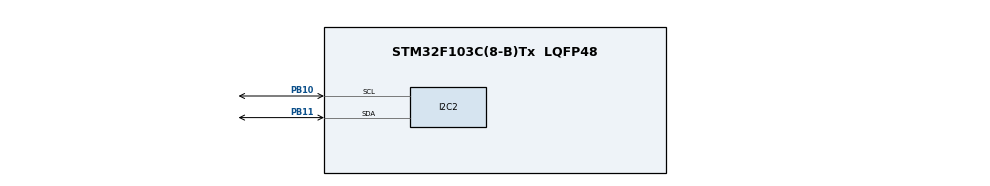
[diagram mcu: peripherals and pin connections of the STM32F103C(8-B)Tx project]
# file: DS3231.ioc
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Mcu.Family=STM32F1
Mcu.Name=STM32F103C(8-B)Tx
Mcu.Package=LQFP48
NVIC.PriorityGroup=NVIC_PRIORITYGROUP_4
PA13.Mode=Serial_Wire
PA13.Signal=SYS_JTMS-SWDIO
PA14.Mode=Serial_Wire
PA14.Signal=SYS_JTCK-SWCLK
PB10.Mode=I2C
PB10.Signal=I2C2_SCL
PB11.Mode=I2C
PB11.Signal=I2C2_SDA
ProjectManager.HeapSize=0x200
ProjectManager.StackSize=0x400
ProjectManager.TargetToolchain=MDK-ARM V5.32
RCC.APB1Freq_Value=8000000
RCC.APB2Freq_Value=8000000
board=custom

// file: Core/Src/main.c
/* USER CODE BEGIN Header */
/**
  ******************************************************************************
  * @file           : main.c
  * @brief          : Main program body
  ******************************************************************************
  * @attention
  *
  * Copyright (c) 2025 STMicroelectronics.
  * All rights reserved.
  *
  * This software is licensed under terms that can be found in the LICENSE file
  * in the root directory of this software component.
  * If no LICENSE file comes with this software, it is provided AS-IS.
  *
  ******************************************************************************
  */
/* USER CODE END Header */
#include "main.h"
#include "DS3231.h"

I2C_HandleTypeDef hi2c2;

void SystemClock_Config(void);
static void MX_GPIO_Init(void);
static void MX_I2C2_Init(void);

/* USER CODE BEGIN 0 */

#define LCD_ADDR (0x27  << 1)
#define LCD_BACKLIGHT 0x08
#define ENABLE 0x04

static void LCD_SendInternal(I2C_HandleTypeDef *hi2c, uint8_t data, uint8_t flags) {
    HAL_StatusTypeDef res;
    uint8_t up = data & 0xF0;
    uint8_t lo = (data << 4) & 0xF0;
    uint8_t data_arr[4];

    data_arr[0] = up | flags | LCD_BACKLIGHT | ENABLE;
    data_arr[1] = up | flags | LCD_BACKLIGHT;
    data_arr[2] = lo | flags | LCD_BACKLIGHT | ENABLE;
    data_arr[3] = lo | flags | LCD_BACKLIGHT;

    res = HAL_I2C_Master_Transmit(hi2c, LCD_ADDR, data_arr, 4, HAL_MAX_DELAY);
    HAL_Delay(1);
}

void LCD_SendCmd(I2C_HandleTypeDef *hi2c, char cmd) {
    LCD_SendInternal(hi2c, cmd, 0);
}

void LCD_SendData(I2C_HandleTypeDef *hi2c, char data) {
    LCD_SendInternal(hi2c, data, 1);
}

void LCD_Init(I2C_HandleTypeDef *hi2c) {
    HAL_Delay(50); // ch? LCD ?n d?nh

    LCD_SendCmd(hi2c, 0x30);
    HAL_Delay(5);
    LCD_SendCmd(hi2c, 0x30);
    HAL_Delay(1);
    LCD_SendCmd(hi2c, 0x30);
    HAL_Delay(10);

    LCD_SendCmd(hi2c, 0x20); // 4-bit mode

    // c?u hЛnh LCD
    LCD_SendCmd(hi2c, 0x28); // 4-bit, 2 line, 5x8 font
    LCD_SendCmd(hi2c, 0x08); // display off
    LCD_SendCmd(hi2c, 0x01); // clear display
    HAL_Delay(2);
    LCD_SendCmd(hi2c, 0x06); // entry mode
    LCD_SendCmd(hi2c, 0x0C); // display on, cursor off, blink off
}

void LCD_SendString(I2C_HandleTypeDef *hi2c, char *str) {
    while (*str) {
        LCD_SendData(hi2c, *str++);
    }
}

void LCD_SetCursor(I2C_HandleTypeDef *hi2c, uint8_t row, uint8_t col) {
    uint8_t addr = (row == 0) ? 0x80 : 0xC0;
    addr += col;
    LCD_SendCmd(hi2c, addr);
}

/* USER CODE END 0 */

int main(void)
{

  /* MCU Configuration--------------------------------------------------------*/

  /* Reset of all peripherals, Initializes the Flash interface and the Systick. */
  HAL_Init();

  /* Configure the system clock */
  SystemClock_Config();

  /* Initialize all configured peripherals */
  MX_GPIO_Init();
  MX_I2C2_Init();
  /* USER CODE BEGIN 2 */

	LCD_Init(&hi2c2);
  LCD_SetCursor(&hi2c2, 0, 0);
  LCD_SendString(&hi2c2, "Hello");

  /* Infinite loop */
  while (1)
  {

  }
}

void SystemClock_Config(void)
{
  RCC_OscInitTypeDef RCC_OscInitStruct = {0};
  RCC_ClkInitTypeDef RCC_ClkInitStruct = {0};

  /** Initializes the RCC Oscillators according to the specified parameters
  * in the RCC_OscInitTypeDef structure.
  */
  RCC_OscInitStruct.OscillatorType = RCC_OSCILLATORTYPE_HSI;
  RCC_OscInitStruct.HSIState = RCC_HSI_ON;
  RCC_OscInitStruct.HSICalibrationValue = RCC_HSICALIBRATION_DEFAULT;
  RCC_OscInitStruct.PLL.PLLState = RCC_PLL_NONE;
  if (HAL_RCC_OscConfig(&RCC_OscInitStruct) != HAL_OK)
  {
    Error_Handler();
  }

  /** Initializes the CPU, AHB and APB buses clocks
  */
  RCC_ClkInitStruct.ClockType = RCC_CLOCKTYPE_HCLK|RCC_CLOCKTYPE_SYSCLK
                              |RCC_CLOCKTYPE_PCLK1|RCC_CLOCKTYPE_PCLK2;
  RCC_ClkInitStruct.SYSCLKSource = RCC_SYSCLKSOURCE_HSI;
  RCC_ClkInitStruct.AHBCLKDivider = RCC_SYSCLK_DIV1;
  RCC_ClkInitStruct.APB1CLKDivider = RCC_HCLK_DIV1;
  RCC_ClkInitStruct.APB2CLKDivider = RCC_HCLK_DIV1;

  if (HAL_RCC_ClockConfig(&RCC_ClkInitStruct, FLASH_LATENCY_0) != HAL_OK)
  {
    Error_Handler();
  }
}

static void MX_I2C2_Init(void)
{

  hi2c2.Instance = I2C2;
  hi2c2.Init.ClockSpeed = 100000;
  hi2c2.Init.DutyCycle = I2C_DUTYCYCLE_2;
  hi2c2.Init.OwnAddress1 = 0;
  hi2c2.Init.AddressingMode = I2C_ADDRESSINGMODE_7BIT;
  hi2c2.Init.DualAddressMode = I2C_DUALADDRESS_DISABLE;
  hi2c2.Init.OwnAddress2 = 0;
  hi2c2.Init.GeneralCallMode = I2C_GENERALCALL_DISABLE;
  hi2c2.Init.NoStretchMode = I2C_NOSTRETCH_DISABLE;
  if (HAL_I2C_Init(&hi2c2) != HAL_OK)
  {
    Error_Handler();
  }

}

static void MX_GPIO_Init(void)
{

  /* GPIO Ports Clock Enable */
  __HAL_RCC_GPIOB_CLK_ENABLE();
  __HAL_RCC_GPIOA_CLK_ENABLE();

}

void Error_Handler(void)
{
  __disable_irq();
  while (1)
  {
  }
}
